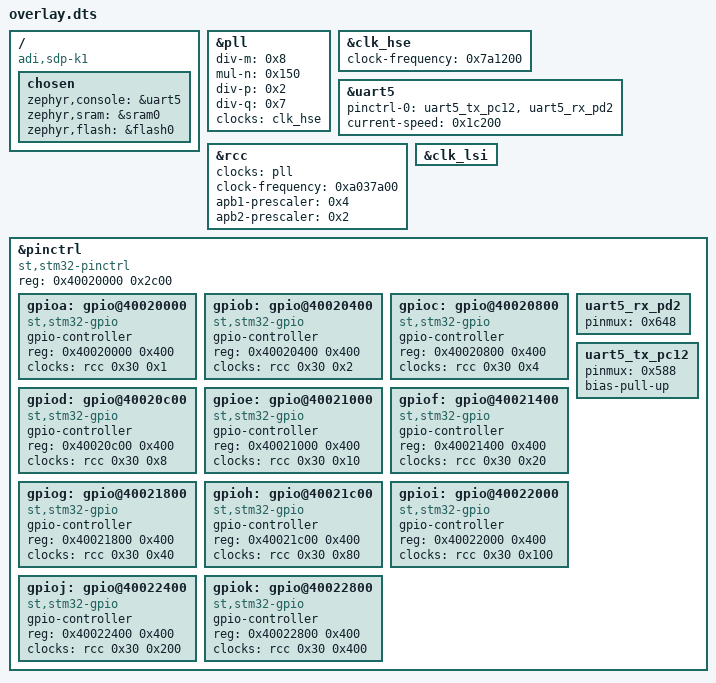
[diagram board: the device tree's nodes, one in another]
/ {
	compatible = "adi,sdp-k1";
	chosen {
		zephyr,console = &uart5;
		zephyr,sram = &sram0;
		zephyr,flash = &flash0;
	};
};
&pll{
	status = "okay";
	div-m = < 0x8 >;
	mul-n = < 0x150 >;
	div-p = < 0x2 >;
	div-q = < 0x7 >;
	clocks = < &clk_hse >;
};
&clk_hse{
	status = "okay";
	clock-frequency = < 0x7a1200 >;
};
&uart5{
	status = "okay";
	pinctrl-0 = < &uart5_tx_pc12 &uart5_rx_pd2 >;
	pinctrl-names = "default";
	current-speed = < 0x1c200 >;
};
&rcc{
	clocks = < &pll >;
	clock-frequency = < 0xa037a00 >;
	apb1-prescaler = < 0x4 >;
	apb2-prescaler = < 0x2 >;
};
&clk_lsi{
	status = "okay";
};
&pinctrl{
	compatible = "st,stm32-pinctrl";
	#address-cells = < 0x1 >;
	#size-cells = < 0x1 >;
	reg = < 0x40020000 0x2c00 >;
	gpioa: gpio@40020000 {
		compatible = "st,stm32-gpio";
		gpio-controller;
		#gpio-cells = < 0x2 >;
		reg = < 0x40020000 0x400 >;
		clocks = < &rcc 0x30 0x1 >;
	};
	gpiob: gpio@40020400 {
		compatible = "st,stm32-gpio";
		gpio-controller;
		#gpio-cells = < 0x2 >;
		reg = < 0x40020400 0x400 >;
		clocks = < &rcc 0x30 0x2 >;
	};
	gpioc: gpio@40020800 {
		compatible = "st,stm32-gpio";
		gpio-controller;
		#gpio-cells = < 0x2 >;
		reg = < 0x40020800 0x400 >;
		clocks = < &rcc 0x30 0x4 >;
	};
	gpiod: gpio@40020c00 {
		compatible = "st,stm32-gpio";
		gpio-controller;
		#gpio-cells = < 0x2 >;
		reg = < 0x40020c00 0x400 >;
		clocks = < &rcc 0x30 0x8 >;
	};
	gpioe: gpio@40021000 {
		compatible = "st,stm32-gpio";
		gpio-controller;
		#gpio-cells = < 0x2 >;
		reg = < 0x40021000 0x400 >;
		clocks = < &rcc 0x30 0x10 >;
	};
	gpiof: gpio@40021400 {
		compatible = "st,stm32-gpio";
		gpio-controller;
		#gpio-cells = < 0x2 >;
		reg = < 0x40021400 0x400 >;
		clocks = < &rcc 0x30 0x20 >;
	};
	gpiog: gpio@40021800 {
		compatible = "st,stm32-gpio";
		gpio-controller;
		#gpio-cells = < 0x2 >;
		reg = < 0x40021800 0x400 >;
		clocks = < &rcc 0x30 0x40 >;
	};
	gpioh: gpio@40021c00 {
		compatible = "st,stm32-gpio";
		gpio-controller;
		#gpio-cells = < 0x2 >;
		reg = < 0x40021c00 0x400 >;
		clocks = < &rcc 0x30 0x80 >;
	};
	gpioi: gpio@40022000 {
		compatible = "st,stm32-gpio";
		gpio-controller;
		#gpio-cells = < 0x2 >;
		reg = < 0x40022000 0x400 >;
		clocks = < &rcc 0x30 0x100 >;
	};
	gpioj: gpio@40022400 {
		compatible = "st,stm32-gpio";
		gpio-controller;
		#gpio-cells = < 0x2 >;
		reg = < 0x40022400 0x400 >;
		clocks = < &rcc 0x30 0x200 >;
	};
	gpiok: gpio@40022800 {
		compatible = "st,stm32-gpio";
		gpio-controller;
		#gpio-cells = < 0x2 >;
		reg = < 0x40022800 0x400 >;
		clocks = < &rcc 0x30 0x400 >;
	};
	uart5_rx_pd2: uart5_rx_pd2 {
		pinmux = < 0x648 >;
	};
	uart5_tx_pc12: uart5_tx_pc12 {
		pinmux = < 0x588 >;
		bias-pull-up;
	};
};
